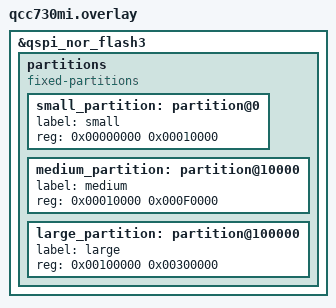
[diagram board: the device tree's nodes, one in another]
#include <mem.h>

//&qspi_nor_flash1 {
	//    status = "okay";
	//    partitions {
		//        compatible = "fixed-partitions";
		//        #address-cells = <1>;
		//        #size-cells = <1>;
		//
		//        storage_partition: partition@0 {
			//            label = "storage";
			//            reg = <0x0 0x400000>;
		//        };
	//    };
//};

//&qspi_nor_flash2 {
	//    status = "okay";
	//    partitions {
		//        compatible = "fixed-partitions";
		//        #address-cells = <1>;
		//        #size-cells = <1>;
		//
		//        storage_partition: partition@0 {
			//            label = "storage";
			//            reg = <0x0 0x400000>;
		//        };
	//    };
//};

&qspi_nor_flash3 {
	status = "okay";
	partitions {
		compatible = "fixed-partitions";
		#address-cells = <1>;
		#size-cells = <1>;

		small_partition: partition@0 {
			label = "small";
			reg = <0x00000000 0x00010000>;
		};
		medium_partition: partition@10000 {
			label = "medium";
			reg = <0x00010000 0x000F0000>;
		};
		large_partition: partition@100000 {
			label = "large";
			reg = <0x00100000 0x00300000>;
		};
	};
};
